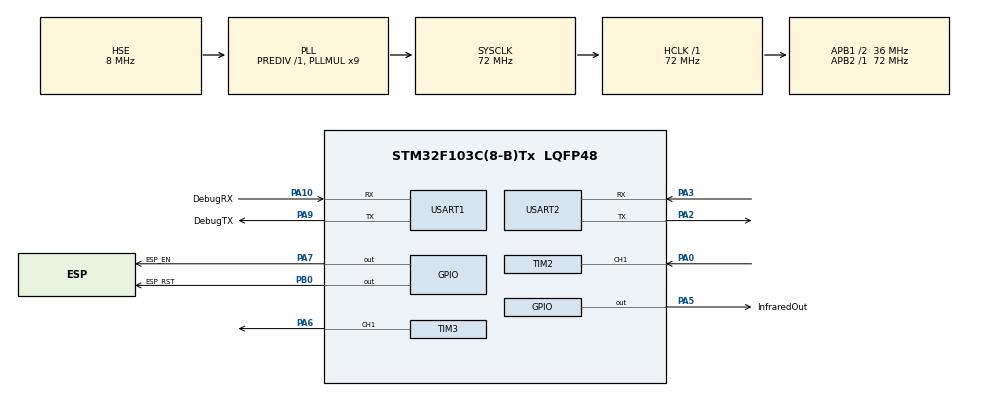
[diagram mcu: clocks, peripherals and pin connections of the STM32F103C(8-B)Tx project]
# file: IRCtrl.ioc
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Dma.Request0=USART1_TX
Dma.Request1=USART2_TX
Dma.Request2=USART1_RX
Dma.Request3=USART2_RX
Dma.USART1_RX.2.Direction=DMA_PERIPH_TO_MEMORY
Dma.USART1_RX.2.Instance=DMA1_Channel5
Dma.USART1_RX.2.MemDataAlignment=DMA_MDATAALIGN_BYTE
Dma.USART1_RX.2.MemInc=DMA_MINC_ENABLE
Dma.USART1_RX.2.Mode=DMA_NORMAL
Dma.USART1_RX.2.PeriphDataAlignment=DMA_PDATAALIGN_BYTE
Dma.USART1_RX.2.PeriphInc=DMA_PINC_DISABLE
Dma.USART1_RX.2.Priority=DMA_PRIORITY_LOW
Dma.USART1_TX.0.Direction=DMA_MEMORY_TO_PERIPH
Dma.USART1_TX.0.Instance=DMA1_Channel4
Dma.USART1_TX.0.MemDataAlignment=DMA_MDATAALIGN_BYTE
Dma.USART1_TX.0.MemInc=DMA_MINC_ENABLE
Dma.USART1_TX.0.Mode=DMA_NORMAL
Dma.USART1_TX.0.PeriphDataAlignment=DMA_PDATAALIGN_BYTE
Dma.USART1_TX.0.PeriphInc=DMA_PINC_DISABLE
Dma.USART1_TX.0.Priority=DMA_PRIORITY_LOW
Dma.USART2_RX.3.Direction=DMA_PERIPH_TO_MEMORY
Dma.USART2_RX.3.Instance=DMA1_Channel6
Dma.USART2_RX.3.MemDataAlignment=DMA_MDATAALIGN_BYTE
Dma.USART2_RX.3.MemInc=DMA_MINC_ENABLE
Dma.USART2_RX.3.Mode=DMA_NORMAL
Dma.USART2_RX.3.PeriphDataAlignment=DMA_PDATAALIGN_BYTE
Dma.USART2_RX.3.PeriphInc=DMA_PINC_DISABLE
Dma.USART2_RX.3.Priority=DMA_PRIORITY_LOW
Dma.USART2_TX.1.Direction=DMA_MEMORY_TO_PERIPH
Dma.USART2_TX.1.Instance=DMA1_Channel7
Dma.USART2_TX.1.MemDataAlignment=DMA_MDATAALIGN_BYTE
Dma.USART2_TX.1.MemInc=DMA_MINC_ENABLE
Dma.USART2_TX.1.Mode=DMA_NORMAL
Dma.USART2_TX.1.PeriphDataAlignment=DMA_PDATAALIGN_BYTE
Dma.USART2_TX.1.PeriphInc=DMA_PINC_DISABLE
Dma.USART2_TX.1.Priority=DMA_PRIORITY_LOW
Mcu.Family=STM32F1
Mcu.Name=STM32F103C(8-B)Tx
Mcu.Package=LQFP48
NVIC.DMA1_Channel4_IRQn=true\:0\:0\:false\:true\:true\:1\:false
NVIC.DMA1_Channel5_IRQn=true\:0\:0\:false\:true\:true\:2\:false
NVIC.DMA1_Channel6_IRQn=true\:0\:0\:false\:true\:true\:3\:false
NVIC.DMA1_Channel7_IRQn=true\:0\:0\:false\:true\:true\:4\:false
NVIC.PriorityGroup=NVIC_PRIORITYGROUP_4
NVIC.TIM1_UP_IRQn=true\:3\:0\:true\:false\:true\:true
NVIC.TIM2_IRQn=true\:1\:0\:true\:true\:true\:5\:true
NVIC.TIM3_IRQn=true\:1\:0\:true\:true\:true\:6\:true
NVIC.USART1_IRQn=true\:0\:0\:true\:false\:true\:true
NVIC.USART2_IRQn=true\:0\:0\:false\:false\:true\:true
PA0-WKUP.Signal=S_TIM2_CH1_ETR
PA10.GPIO_Label=DebugRX
PA10.Mode=Asynchronous
PA10.Signal=USART1_RX
PA2.Mode=Asynchronous
PA2.Signal=USART2_TX
PA3.Mode=Asynchronous
PA3.Signal=USART2_RX
PA5.GPIO_Label=InfraredOut
PA5.Signal=GPIO_Output
PA6.GPIO_Speed=GPIO_SPEED_FREQ_HIGH
PA6.Signal=S_TIM3_CH1
PA7.GPIO_Label=ESP_EN
PA7.PinState=GPIO_PIN_SET
PA7.Signal=GPIO_Output
PA9.GPIO_Label=DebugTX
PA9.Mode=Asynchronous
PA9.Signal=USART1_TX
PB0.GPIO_Label=ESP_RST
PB0.PinState=GPIO_PIN_SET
PB0.Signal=GPIO_Output
PD0-OSC_IN.Mode=HSE-External-Oscillator
PD0-OSC_IN.Signal=RCC_OSC_IN
PD1-OSC_OUT.Mode=HSE-External-Oscillator
PD1-OSC_OUT.Signal=RCC_OSC_OUT
ProjectManager.HeapSize=0x200
ProjectManager.StackSize=0x400
ProjectManager.TargetToolchain=MDK-ARM V5
RCC.AHBFreq_Value=72000000
RCC.APB1CLKDivider=RCC_HCLK_DIV2
RCC.APB1Freq_Value=36000000
RCC.APB1TimFreq_Value=72000000
RCC.APB2Freq_Value=72000000
RCC.APB2TimFreq_Value=72000000
RCC.HCLKFreq_Value=72000000
RCC.PLLMUL=RCC_PLL_MUL9
RCC.PLLSourceVirtual=RCC_PLLSOURCE_HSE
RCC.SYSCLKFreq_VALUE=72000000
RCC.SYSCLKSource=RCC_SYSCLKSOURCE_PLLCLK
RCC.USBFreq_Value=72000000
SH.S_TIM2_CH1_ETR.0=TIM2_CH1,PWM_Input_1
SH.S_TIM3_CH1.0=TIM3_CH1,PWM Generation1 CH1
TIM1.Period=2999
TIM1.Prescaler=7199
TIM2.ICPolarity_1=TIM_INPUTCHANNELPOLARITY_FALLING
TIM2.Period=5999
TIM2.Prescaler=3599
TIM2.TIM_MasterOutputTrigger=TIM_TRGO_UPDATE
TIM3.Channel-PWM\ Generation1\ CH1=TIM_CHANNEL_1
TIM3.Period=209
TIM3.Prescaler=8
TIM3.Pulse-PWM\ Generation1\ CH1=33
USART1.VirtualMode=VM_ASYNC
USART2.VirtualMode=VM_ASYNC
VP_SYS_VS_ND.Mode=No_Debug
VP_TIM1_VS_ClockSourceINT.Mode=Internal
VP_TIM2_VS_ClockSourceINT.Mode=Internal
VP_TIM3_VS_ClockSourceINT.Mode=Internal
board=IRCtrl

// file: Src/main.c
/**
  ******************************************************************************
  * @file           : main.c
  * @brief          : Main program body
  ******************************************************************************
  ** This notice applies to any and all portions of this file
  * that are not between comment pairs USER CODE BEGIN and
  * USER CODE END. Other portions of this file, whether
  * inserted by the user or by software development tools
  * are owned by their respective copyright owners.
  *
  * COPYRIGHT(c) 2018 STMicroelectronics
  *
  * Redistribution and use in source and binary forms, with or without modification,
  * are permitted provided that the following conditions are met:
  *   1. Redistributions of source code must retain the above copyright notice,
  *      this list of conditions and the following disclaimer.
  *   2. Redistributions in binary form must reproduce the above copyright notice,
  *      this list of conditions and the following disclaimer in the documentation
  *      and/or other materials provided with the distribution.
  *   3. Neither the name of STMicroelectronics nor the names of its contributors
  *      may be used to endorse or promote products derived from this software
  *      without specific prior written permission.
  *
  * THIS SOFTWARE IS PROVIDED BY THE COPYRIGHT HOLDERS AND CONTRIBUTORS "AS IS"
  * AND ANY EXPRESS OR IMPLIED WARRANTIES, INCLUDING, BUT NOT LIMITED TO, THE
  * IMPLIED WARRANTIES OF MERCHANTABILITY AND FITNESS FOR A PARTICULAR PURPOSE ARE
  * DISCLAIMED. IN NO EVENT SHALL THE COPYRIGHT HOLDER OR CONTRIBUTORS BE LIABLE
  * FOR ANY DIRECT, INDIRECT, INCIDENTAL, SPECIAL, EXEMPLARY, OR CONSEQUENTIAL
  * DAMAGES (INCLUDING, BUT NOT LIMITED TO, PROCUREMENT OF SUBSTITUTE GOODS OR
  * SERVICES; LOSS OF USE, DATA, OR PROFITS; OR BUSINESS INTERRUPTION) HOWEVER
  * CAUSED AND ON ANY THEORY OF LIABILITY, WHETHER IN CONTRACT, STRICT LIABILITY,
  * OR TORT (INCLUDING NEGLIGENCE OR OTHERWISE) ARISING IN ANY WAY OUT OF THE USE
  * OF THIS SOFTWARE, EVEN IF ADVISED OF THE POSSIBILITY OF SUCH DAMAGE.
  *
  ******************************************************************************
  */
#include "main.h"
#include "stm32f1xx_hal.h"
#include "dma.h"
#include "tim.h"
#include "usart.h"
#include "gpio.h"
#include "ir_ctrl.h"

/* USER CODE BEGIN PV */
/* Private variables ---------------------------------------------------------*/

/* USER CODE END PV */

void SystemClock_Config(void);
static void MX_NVIC_Init(void);

/* USER CODE BEGIN PFP */
/* Private function prototypes -----------------------------------------------*/

/* USER CODE END PFP */

int main(void)
{

  /* MCU Configuration----------------------------------------------------------*/

  /* Reset of all peripherals, Initializes the Flash interface and the Systick. */
  HAL_Init();

  /* Configure the system clock */
  SystemClock_Config();

  /* Initialize all configured peripherals */
  MX_GPIO_Init();
  MX_DMA_Init();
  MX_USART1_UART_Init();
  MX_USART2_UART_Init();
	Uart1Init();
	Uart2Init();
  MX_TIM2_Init();
  MX_TIM3_Init();
  MX_TIM1_Init();
	IR_init();
  /* Initialize interrupts */
  MX_NVIC_Init();
  /* USER CODE BEGIN 2 */
	printf("init ok \r\n");
	//StartTimCapture();
	TestIrSend();

  /* USER CODE END 2 */

  /* Infinite loop */
  while (1)
  {

  }

}

void SystemClock_Config(void)
{

  RCC_OscInitTypeDef RCC_OscInitStruct;
  RCC_ClkInitTypeDef RCC_ClkInitStruct;

    /**Initializes the CPU, AHB and APB busses clocks
    */
  RCC_OscInitStruct.OscillatorType = RCC_OSCILLATORTYPE_HSE;
  RCC_OscInitStruct.HSEState = RCC_HSE_ON;
  RCC_OscInitStruct.HSEPredivValue = RCC_HSE_PREDIV_DIV1;
  RCC_OscInitStruct.HSIState = RCC_HSI_ON;
  RCC_OscInitStruct.PLL.PLLState = RCC_PLL_ON;
  RCC_OscInitStruct.PLL.PLLSource = RCC_PLLSOURCE_HSE;
  RCC_OscInitStruct.PLL.PLLMUL = RCC_PLL_MUL9;
  if (HAL_RCC_OscConfig(&RCC_OscInitStruct) != HAL_OK)
  {
    _Error_Handler(__FILE__, __LINE__);
  }

    /**Initializes the CPU, AHB and APB busses clocks
    */
  RCC_ClkInitStruct.ClockType = RCC_CLOCKTYPE_HCLK|RCC_CLOCKTYPE_SYSCLK
                              |RCC_CLOCKTYPE_PCLK1|RCC_CLOCKTYPE_PCLK2;
  RCC_ClkInitStruct.SYSCLKSource = RCC_SYSCLKSOURCE_PLLCLK;
  RCC_ClkInitStruct.AHBCLKDivider = RCC_SYSCLK_DIV1;
  RCC_ClkInitStruct.APB1CLKDivider = RCC_HCLK_DIV2;
  RCC_ClkInitStruct.APB2CLKDivider = RCC_HCLK_DIV1;

  if (HAL_RCC_ClockConfig(&RCC_ClkInitStruct, FLASH_LATENCY_2) != HAL_OK)
  {
    _Error_Handler(__FILE__, __LINE__);
  }

    /**Configure the Systick interrupt time
    */
  HAL_SYSTICK_Config(HAL_RCC_GetHCLKFreq()/100000);

    /**Configure the Systick
    */
  HAL_SYSTICK_CLKSourceConfig(SYSTICK_CLKSOURCE_HCLK);

  /* SysTick_IRQn interrupt configuration */
  HAL_NVIC_SetPriority(SysTick_IRQn, 0, 0);
}

/**
  * @brief NVIC Configuration.
  * @retval None
  */
static void MX_NVIC_Init(void)
{
  /* DMA1_Channel4_IRQn interrupt configuration */
  HAL_NVIC_SetPriority(DMA1_Channel4_IRQn, 0, 0);
  HAL_NVIC_EnableIRQ(DMA1_Channel4_IRQn);
  /* DMA1_Channel5_IRQn interrupt configuration */
  HAL_NVIC_SetPriority(DMA1_Channel5_IRQn, 0, 0);
  HAL_NVIC_EnableIRQ(DMA1_Channel5_IRQn);
  /* DMA1_Channel6_IRQn interrupt configuration */
  HAL_NVIC_SetPriority(DMA1_Channel6_IRQn, 0, 0);
  HAL_NVIC_EnableIRQ(DMA1_Channel6_IRQn);
  /* DMA1_Channel7_IRQn interrupt configuration */
  HAL_NVIC_SetPriority(DMA1_Channel7_IRQn, 0, 0);
  HAL_NVIC_EnableIRQ(DMA1_Channel7_IRQn);
  /* TIM2_IRQn interrupt configuration */
  HAL_NVIC_SetPriority(TIM2_IRQn, 1, 0);
  HAL_NVIC_EnableIRQ(TIM2_IRQn);
  /* TIM3_IRQn interrupt configuration */
  HAL_NVIC_SetPriority(TIM3_IRQn, 1, 0);
  HAL_NVIC_EnableIRQ(TIM3_IRQn);
}

void _Error_Handler(char *file, int line)
{
  while(1)
  {
  }
}

/************************ (C) COPYRIGHT STMicroelectronics *****END OF FILE****/
